# STM32WBA24 register map
File version: 0.2
CPU: CM33 r0p1, little endian, MPU, FPU, 4 interrupt priority bits
Registers are 32-bit, read-write, reset 0x0 unless marked. A register's access mark holds for its fields unless they carry their own. Offsets are from the block's base; [hi:lo] are bit positions; {n}, {i} and the like mark numbered series; 'fields as' and 'values as' point back to an identical list.

## ADC4 — ADC4 address block description
Base 0x46021000
Same registers: SEC_ADC4 0x56021000
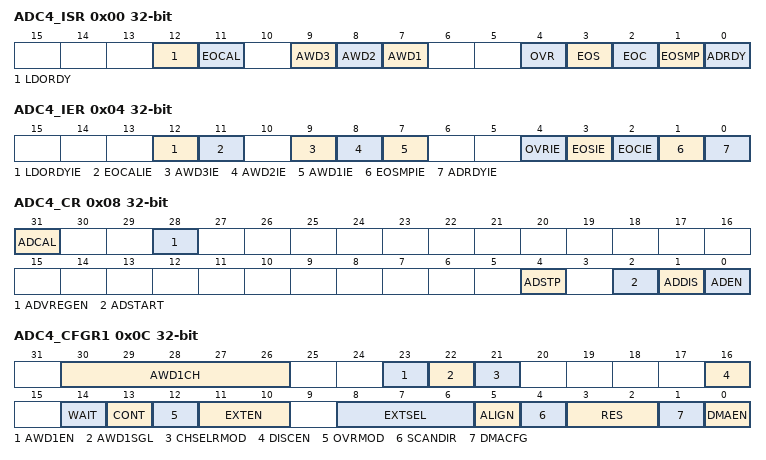
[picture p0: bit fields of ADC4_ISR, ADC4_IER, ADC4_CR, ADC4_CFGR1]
0x00 ADC4_ISR — ADC interrupt and status register
  [12] LDORDY — LDO ready
    0=ADC voltage regulator disabled; 1=ADC voltage regulator enabled and stabilized
  [11] EOCAL — End of calibration flag
    0=Calibration is not complete; 1=Calibration is complete
  [9] AWD3 — Analog watchdog 3 flag
    0=No analog watchdog event occurred (or the flag event was already acknowledged and cleared by software); 1=Analog watchdog event occurred
  [8] AWD2 — Analog watchdog 2 flag
    values as AWD3
  [7] AWD1 — Analog watchdog 1 flag
    values as AWD3
  [4] OVR — ADC overrun
    0=No overrun occurred (or the flag event was already acknowledged and cleared by software); 1=Overrun has occurred
  [3] EOS — End of sequence flag
    0=Conversion sequence not complete (or the flag event was already acknowledged and cleared by software); 1=Conversion sequence complete
  [2] EOC — End of conversion flag
    0=Channel conversion not complete (or the flag event was already acknowledged and cleared by software); 1=Channel conversion complete
  [1] EOSMP — End of sampling flag
    0=Not at the end of the sampling phase (or the flag event was already acknowledged and cleared by software); 1=End of sampling phase reached
  [0] ADRDY — ADC ready
    0=ADC not yet ready to start conversion (or the flag event was already acknowledged and cleared by software); 1=ADC is ready to start conversion
0x04 ADC4_IER — ADC interrupt enable register
  [12] LDORDYIE — LDO ready interrupt enable
    0=LDO ready interrupt disabled; 1=LDO ready interrupt enabled
  [11] EOCALIE — End of calibration interrupt enable
    0=End of calibration interrupt disabled; 1=End of calibration interrupt enabled
  [9] AWD3IE — Analog watchdog 3 interrupt enable
    0=Analog watchdog interrupt disabled; 1=Analog watchdog interrupt enabled
  [8] AWD2IE — Analog watchdog 2 interrupt enable
    values as AWD3IE
  [7] AWD1IE — Analog watchdog 1 interrupt enable
    values as AWD3IE
  [4] OVRIE — Overrun interrupt enable
    0=Overrun interrupt disabled; 1=Overrun interrupt enabled
  [3] EOSIE — End of conversion sequence interrupt enable
    0=EOS interrupt disabled; 1=EOS interrupt enabled
  [2] EOCIE — End of conversion interrupt enable
    0=EOC interrupt disabled; 1=EOC interrupt enabled
  [1] EOSMPIE — End of sampling flag interrupt enable
    0=EOSMP interrupt disabled; 1=EOSMP interrupt enabled
  [0] ADRDYIE — ADC ready interrupt enable
    0=ADRDY interrupt disabled; 1=ADRDY interrupt enabled
0x08 ADC4_CR — ADC control register
  [31] ADCAL — ADC calibration
    0=Calibration complete; 1=Write 1 to calibrate the ADC
  [28] ADVREGEN — ADC voltage regulator enable
    0=ADC voltage regulator disabled; 1=ADC voltage regulator enabled
  [4] ADSTP — ADC stop conversion command
    0=No ADC stop conversion command ongoing; 1=Write 1 to stop the ADC
  [2] ADSTART — ADC start conversion command
    0=No ADC conversion is ongoing; 1=Write 1 to start the ADC
  [1] ADDIS — ADC disable command
    0=No ADDIS command ongoing; 1=Write 1 to disable the ADC
  [0] ADEN — ADC enable command
    0=ADC is disabled (OFF state); 1=Write 1 to enable the ADC
0x0C ADC4_CFGR1 — ADC configuration register 1
  [30:26] AWD1CH — Analog watchdog channel selection
    0=ADC analog input Channel 0 monitored by AWD; 1=ADC analog input Channel 1 monitored by AWD; 11=ADC analog input Channel 11 monitored by AWD
  [23] AWD1EN — Analog watchdog enable
    0=Analog watchdog 1 disabled; 1=Analog watchdog 1 enabled
  [22] AWD1SGL — Enable the watchdog on a single channel or on all channels
    0=Analog watchdog 1 enabled on all channels; 1=Analog watchdog 1 enabled on a single channel
  [21] CHSELRMOD — Mode selection of the ADC_CHSELR register
    0=Each bit of the ADC_CHSELR register enables an input; 1=ADC_CHSELR register is able to sequence up to 8 channels
  [16] DISCEN — Discontinuous mode
    0=Discontinuous mode disabled; 1=Discontinuous mode enabled
  [14] WAIT — Wait conversion mode
    0=Wait conversion mode off; 1=Wait conversion mode on
  [13] CONT — Single / continuous conversion mode
    0=Single conversion mode; 1=Continuous conversion mode
  [12] OVRMOD — Overrun management mode
    0=ADC_DR register is preserved with the old data when an overrun is detected; 1=ADC_DR register is overwritten with the last conversion result when an overrun is detected
  [11:10] EXTEN — External trigger enable and polarity selection
    0=Hardware trigger detection disabled (conversions can be started by software); 1=Hardware trigger detection on the rising edge; 2=Hardware trigger detection on the falling edge; 3=Hardware trigger detection on both the rising and falling edges
  [8:6] EXTSEL — External trigger selection
    {v}=adc_trg{v} (v=0..7)
  [5] ALIGN — Data alignment
    0=Right alignment; 1=Left alignment
  [4] SCANDIR — Scan sequence direction
    0=Upward scan (from CHSEL0 to CHSEL11); 1=Backward scan (from CHSEL11 to CHSEL0)
  [3:2] RES — Data resolution
    0=12 bits; 1=10 bits; 2=8 bits; 3=6 bits
  [1] DMACFG — Direct memory access configuration
    0=DMA one shot mode selected; 1=DMA circular mode selected
  [0] DMAEN — Direct memory access enable
    0=DMA disabled; 1=DMA enabled
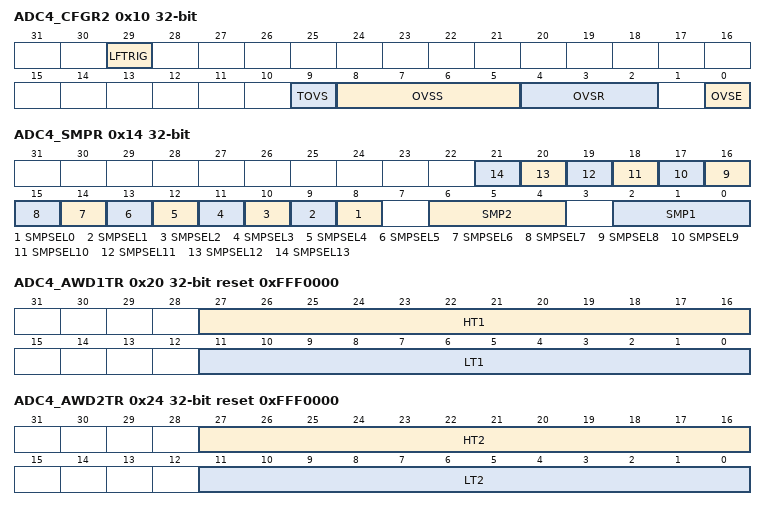
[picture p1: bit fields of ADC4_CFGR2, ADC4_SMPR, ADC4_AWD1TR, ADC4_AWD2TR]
0x10 ADC4_CFGR2 — ADC configuration register 2
  [29] LFTRIG — Low frequency trigger mode enable
    1=Low frequency trigger mode enabled
  [9] TOVS — Triggered Oversampling
    0=All oversampled conversions for a channel are done consecutively after a trigger; 1=Each oversampled conversion for a channel needs a trigger
  [8:5] OVSS — Oversampling shift
    0=No shift; 1=Shift 1-bit; {v}=Shift {v}-bits (v=2..8)
  [4:2] OVSR — Oversampling ratio
    0=2x; 1=4x; 2=8x; 3=16x; 4=32x; 5=64x; 6=128x; 7=256x
  [0] OVSE — Oversampler Enable
    0=Oversampler disabled; 1=Oversampler enabled
0x14 ADC4_SMPR — ADC sampling time register
  [n+8] SMPSEL{n} (n=0..13) — Channel-x sampling time selection (x=13 to 0)
    0=Sampling time of CHANNELx use the setting of SMP1[2:0] register; 1=Sampling time of CHANNELx use the setting of SMP2[2:0] register
  [6:4] SMP2 — Sampling time selection 2
    0=1; 1=3; 2=7; 3=12; 4=19; 5=39; 6=79; 7=814
  [2:0] SMP1 — Sampling time selection 1
    0=1; 1=3; 2=7; 3=12; 4=19; 5=39; 6=79; 7=814
0x20 ADC4_AWD1TR reset 0xFFF0000 — ADC watchdog threshold register
  [27:16] HT1 — Analog watchdog 1 higher threshold
  [11:0] LT1 — Analog watchdog 1 lower threshold
0x24 ADC4_AWD2TR reset 0xFFF0000 — ADC watchdog threshold register
  [27:16] HT2 — Analog watchdog 2 higher threshold
  [11:0] LT2 — Analog watchdog 2 lower threshold
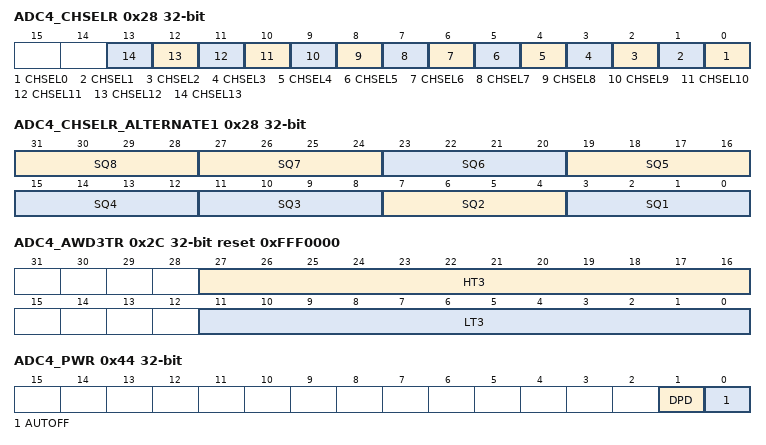
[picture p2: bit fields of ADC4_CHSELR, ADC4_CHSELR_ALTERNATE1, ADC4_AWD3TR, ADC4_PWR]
0x28 ADC4_CHSELR — ADC channel selection register [alternate]
  [all] fields
    0=Input Channel-x is not selected for conversion; 1=Input Channel-x is selected for conversion
  [n] CHSEL{n} (n=0..13) — Channel x selection (x=13 to 0)
0x28 ADC4_CHSELR_ALTERNATE1 (alternate view of ADC4_CHSELR) — ADC channel selection register
  [31:28] SQ8 — 8th conversion of the sequence
    0=CH0; 1=CH1; {v}=CH{v} (v=10..13); 15=No channel selected (End of sequence)
  [4n-1:4n-4] SQ{n} (n=4..7) — {n}th conversion of the sequence
  [11:8] SQ3 — 3rd conversion of the sequence
  [7:4] SQ2 — 2nd conversion of the sequence
  [3:0] SQ1 — 1st conversion of the sequence
0x2C ADC4_AWD3TR reset 0xFFF0000 — ADC watchdog threshold register
  [27:16] HT3 — Analog watchdog 3 higher threshold
  [11:0] LT3 — Analog watchdog 3lower threshold
0x40 ADC4_DR ro — ADC data register
  [15:0] DATA — Converted data
0x44 ADC4_PWR — ADC data register
  [1] DPD — Deep-power-down mode bit
    0=Deep-power-down mode disabled; 1=Deep-power-down mode enabled
  [0] AUTOFF — Auto-off mode bit
    0=Auto-off mode disabled; 1=Auto-off mode enabled
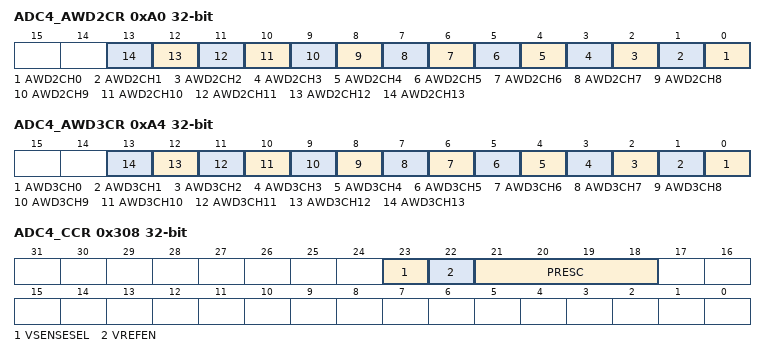
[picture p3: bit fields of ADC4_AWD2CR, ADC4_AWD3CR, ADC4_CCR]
0xA0 ADC4_AWD2CR — ADC Analog Watchdog 2 Configuration register
  [all] fields
    0=ADC analog channel-x is not monitored by AWD2; 1=ADC analog channel-x is monitored by AWD2
  [n] AWD2CH{n} (n=0..13) — Analog watchdog channel selection (x=13 to 0)
0xA4 ADC4_AWD3CR — ADC Analog Watchdog 3 Configuration register
  [all] fields
    0=ADC analog channel-x is not monitored by AWD3; 1=ADC analog channel-x is monitored by AWD3
  [n] AWD3CH{n} (n=0..13) — Analog watchdog channel selection (x=13 to 0)
0xC4 ADC4_CALFACT — ADC Calibration factor
  [6:0] CALFACT — Calibration factor
0x308 ADC4_CCR — ADC common configuration register
  [23] VSENSESEL — Temperature sensor selection
    0=Temperature sensor disabled; 1=Temperature sensor enabled
  [22] VREFEN — Vless thansub>REFINTless than/sub> enable
    0=Vless thansub>REFINTless than/sub> disabled; 1=Vless thansub>REFINTless than/sub> enabled
  [21:18] PRESC — ADC prescaler
    0=input ADC clock not divided; 1=input ADC clock divided by 2; 2=input ADC clock divided by 4; 3=input ADC clock divided by 6; 4=input ADC clock divided by 8; 5=input ADC clock divided by 10; 6=input ADC clock divided by 12; 7=input ADC clock divided by 16; 8=input ADC clock divided by 32; 9=input ADC clock divided by 64; 10=input ADC clock divided by 128; 11=input ADC clock divided by 256

## Notices in the file
Copyright (c) 2025 STMicroelectronics.
SPDX-License-Identifier: Apache-2.0
Licensed under the Apache License, Version 2.0 (the "License");
you may not use this file except in compliance with the License.
You may obtain a copy of the License at
http://www.apache.org/licenses/LICENSE-2.0
Unless required by applicable law or agreed to in writing, software
distributed under the License is distributed on an "AS IS" BASIS,
WITHOUT WARRANTIES OR CONDITIONS OF ANY KIND, either express or implied.
See the License for the specific language governing permissions and
limitations under the License.
